# ESP32-H4 register map
Vendor: ESPRESSIF SYSTEMS (SHANGHAI) CO., LTD.; Series: ESP32 H-Series; File version: 1
CPU: RV32IMAC r0p0, little endian, no MPU, no FPU, 0 interrupt priority bits
Address unit: 32 bits
Registers are 32-bit, read-write, reset 0x0 unless marked. A register's access mark holds for its fields unless they carry their own. Offsets are from the block's base; [hi:lo] are bit positions.

## TEE (part 2 of 2) — TEE Peripheral
Base 0x6009F000
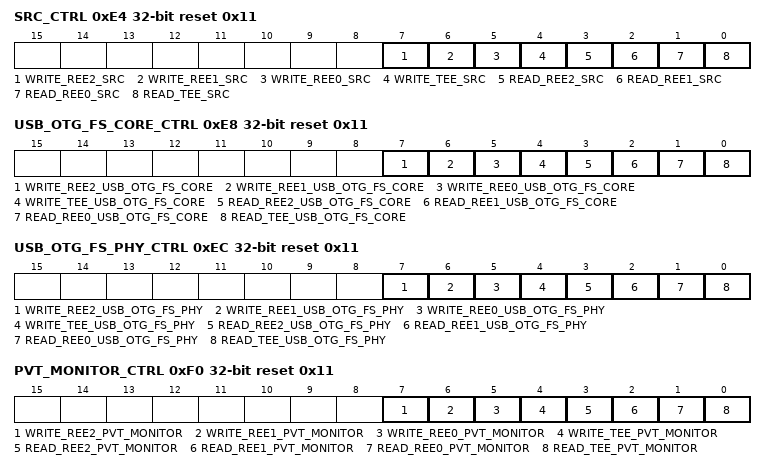
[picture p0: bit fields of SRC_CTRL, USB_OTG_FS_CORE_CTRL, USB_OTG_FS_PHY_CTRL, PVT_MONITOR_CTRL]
0xE4 SRC_CTRL reset 0x11 — src read/write control register
  [7] WRITE_REE2_SRC — Configures src registers write permission in ree2 mode.\\ 0: can not be write \\ 1: can be write \\
  [6] WRITE_REE1_SRC — Configures src registers write permission in ree1 mode.\\ 0: can not be write \\ 1: can be write \\
  [5] WRITE_REE0_SRC — Configures src registers write permission in ree0 mode.\\ 0: can not be write \\ 1: can be write \\
  [4] WRITE_TEE_SRC — Configures src registers write permission in tee mode.\\ 0: can not be write \\ 1: can be write \\
  [3] READ_REE2_SRC — Configures src registers read permission in ree2 mode.\\ 0: can not be read \\ 1: can be read \\
  [2] READ_REE1_SRC — Configures src registers read permission in ree1 mode.\\ 0: can not be read \\ 1: can be read \\
  [1] READ_REE0_SRC — Configures src registers read permission in ree0 mode.\\ 0: can not be read \\ 1: can be read \\
  [0] READ_TEE_SRC — Configures src registers read permission in tee mode.\\ 0: can not be read \\ 1: can be read \\
0xE8 USB_OTG_FS_CORE_CTRL reset 0x11 — usb_otg_fs_core read/write control register
  [7] WRITE_REE2_USB_OTG_FS_CORE — Configures usb_otg_fs_core registers write permission in ree2 mode.\\ 0: can not be write \\ 1: can be write \\
  [6] WRITE_REE1_USB_OTG_FS_CORE — Configures usb_otg_fs_core registers write permission in ree1 mode.\\ 0: can not be write \\ 1: can be write \\
  [5] WRITE_REE0_USB_OTG_FS_CORE — Configures usb_otg_fs_core registers write permission in ree0 mode.\\ 0: can not be write \\ 1: can be write \\
  [4] WRITE_TEE_USB_OTG_FS_CORE — Configures usb_otg_fs_core registers write permission in tee mode.\\ 0: can not be write \\ 1: can be write \\
  [3] READ_REE2_USB_OTG_FS_CORE — Configures usb_otg_fs_core registers read permission in ree2 mode.\\ 0: can not be read \\ 1: can be read \\
  [2] READ_REE1_USB_OTG_FS_CORE — Configures usb_otg_fs_core registers read permission in ree1 mode.\\ 0: can not be read \\ 1: can be read \\
  [1] READ_REE0_USB_OTG_FS_CORE — Configures usb_otg_fs_core registers read permission in ree0 mode.\\ 0: can not be read \\ 1: can be read \\
  [0] READ_TEE_USB_OTG_FS_CORE — Configures usb_otg_fs_core registers read permission in tee mode.\\ 0: can not be read \\ 1: can be read \\
0xEC USB_OTG_FS_PHY_CTRL reset 0x11 — usb_otg_fs_phy read/write control register
  [7] WRITE_REE2_USB_OTG_FS_PHY — Configures usb_otg_fs_phy registers write permission in ree2 mode.\\ 0: can not be write \\ 1: can be write \\
  [6] WRITE_REE1_USB_OTG_FS_PHY — Configures usb_otg_fs_phy registers write permission in ree1 mode.\\ 0: can not be write \\ 1: can be write \\
  [5] WRITE_REE0_USB_OTG_FS_PHY — Configures usb_otg_fs_phy registers write permission in ree0 mode.\\ 0: can not be write \\ 1: can be write \\
  [4] WRITE_TEE_USB_OTG_FS_PHY — Configures usb_otg_fs_phy registers write permission in tee mode.\\ 0: can not be write \\ 1: can be write \\
  [3] READ_REE2_USB_OTG_FS_PHY — Configures usb_otg_fs_phy registers read permission in ree2 mode.\\ 0: can not be read \\ 1: can be read \\
  [2] READ_REE1_USB_OTG_FS_PHY — Configures usb_otg_fs_phy registers read permission in ree1 mode.\\ 0: can not be read \\ 1: can be read \\
  [1] READ_REE0_USB_OTG_FS_PHY — Configures usb_otg_fs_phy registers read permission in ree0 mode.\\ 0: can not be read \\ 1: can be read \\
  [0] READ_TEE_USB_OTG_FS_PHY — Configures usb_otg_fs_phy registers read permission in tee mode.\\ 0: can not be read \\ 1: can be read \\
0xF0 PVT_MONITOR_CTRL reset 0x11 — pvt_monitor read/write control register
  [7] WRITE_REE2_PVT_MONITOR — Configures pvt_monitor registers write permission in ree2 mode.\\ 0: can not be write \\ 1: can be write \\
  [6] WRITE_REE1_PVT_MONITOR — Configures pvt_monitor registers write permission in ree1 mode.\\ 0: can not be write \\ 1: can be write \\
  [5] WRITE_REE0_PVT_MONITOR — Configures pvt_monitor registers write permission in ree0 mode.\\ 0: can not be write \\ 1: can be write \\
  [4] WRITE_TEE_PVT_MONITOR — Configures pvt_monitor registers write permission in tee mode.\\ 0: can not be write \\ 1: can be write \\
  [3] READ_REE2_PVT_MONITOR — Configures pvt_monitor registers read permission in ree2 mode.\\ 0: can not be read \\ 1: can be read \\
  [2] READ_REE1_PVT_MONITOR — Configures pvt_monitor registers read permission in ree1 mode.\\ 0: can not be read \\ 1: can be read \\
  [1] READ_REE0_PVT_MONITOR — Configures pvt_monitor registers read permission in ree0 mode.\\ 0: can not be read \\ 1: can be read \\
  [0] READ_TEE_PVT_MONITOR — Configures pvt_monitor registers read permission in tee mode.\\ 0: can not be read \\ 1: can be read \\
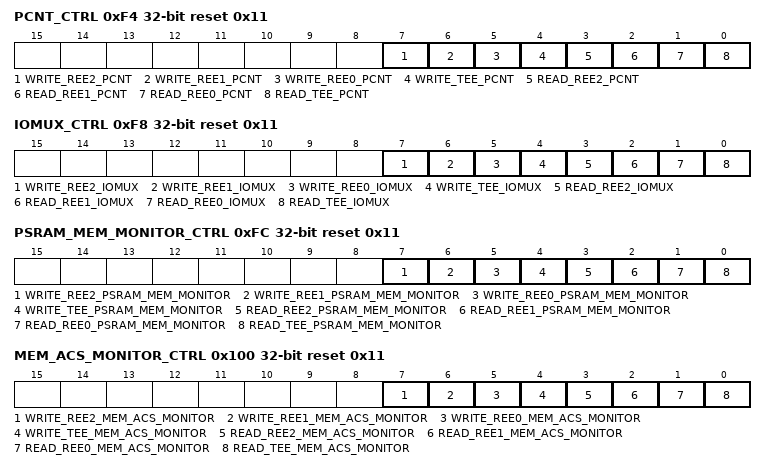
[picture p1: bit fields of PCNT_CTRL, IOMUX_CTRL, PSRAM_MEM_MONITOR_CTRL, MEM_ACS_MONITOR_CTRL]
0xF4 PCNT_CTRL reset 0x11 — pcnt read/write control register
  [7] WRITE_REE2_PCNT — Configures pcnt registers write permission in ree2 mode.\\ 0: can not be write \\ 1: can be write \\
  [6] WRITE_REE1_PCNT — Configures pcnt registers write permission in ree1 mode.\\ 0: can not be write \\ 1: can be write \\
  [5] WRITE_REE0_PCNT — Configures pcnt registers write permission in ree0 mode.\\ 0: can not be write \\ 1: can be write \\
  [4] WRITE_TEE_PCNT — Configures pcnt registers write permission in tee mode.\\ 0: can not be write \\ 1: can be write \\
  [3] READ_REE2_PCNT — Configures pcnt registers read permission in ree2 mode.\\ 0: can not be read \\ 1: can be read \\
  [2] READ_REE1_PCNT — Configures pcnt registers read permission in ree1 mode.\\ 0: can not be read \\ 1: can be read \\
  [1] READ_REE0_PCNT — Configures pcnt registers read permission in ree0 mode.\\ 0: can not be read \\ 1: can be read \\
  [0] READ_TEE_PCNT — Configures pcnt registers read permission in tee mode.\\ 0: can not be read \\ 1: can be read \\
0xF8 IOMUX_CTRL reset 0x11 — iomux read/write control register
  [7] WRITE_REE2_IOMUX — Configures iomux registers write permission in ree2 mode.\\ 0: can not be write \\ 1: can be write \\
  [6] WRITE_REE1_IOMUX — Configures iomux registers write permission in ree1 mode.\\ 0: can not be write \\ 1: can be write \\
  [5] WRITE_REE0_IOMUX — Configures iomux registers write permission in ree0 mode.\\ 0: can not be write \\ 1: can be write \\
  [4] WRITE_TEE_IOMUX — Configures iomux registers write permission in tee mode.\\ 0: can not be write \\ 1: can be write \\
  [3] READ_REE2_IOMUX — Configures iomux registers read permission in ree2 mode.\\ 0: can not be read \\ 1: can be read \\
  [2] READ_REE1_IOMUX — Configures iomux registers read permission in ree1 mode.\\ 0: can not be read \\ 1: can be read \\
  [1] READ_REE0_IOMUX — Configures iomux registers read permission in ree0 mode.\\ 0: can not be read \\ 1: can be read \\
  [0] READ_TEE_IOMUX — Configures iomux registers read permission in tee mode.\\ 0: can not be read \\ 1: can be read \\
0xFC PSRAM_MEM_MONITOR_CTRL reset 0x11 — psram_mem_monitor read/write control register
  [7] WRITE_REE2_PSRAM_MEM_MONITOR — Configures psram_mem_monitor registers write permission in ree2 mode.\\ 0: can not be write \\ 1: can be write \\
  [6] WRITE_REE1_PSRAM_MEM_MONITOR — Configures psram_mem_monitor registers write permission in ree1 mode.\\ 0: can not be write \\ 1: can be write \\
  [5] WRITE_REE0_PSRAM_MEM_MONITOR — Configures psram_mem_monitor registers write permission in ree0 mode.\\ 0: can not be write \\ 1: can be write \\
  [4] WRITE_TEE_PSRAM_MEM_MONITOR — Configures psram_mem_monitor registers write permission in tee mode.\\ 0: can not be write \\ 1: can be write \\
  [3] READ_REE2_PSRAM_MEM_MONITOR — Configures psram_mem_monitor registers read permission in ree2 mode.\\ 0: can not be read \\ 1: can be read \\
  [2] READ_REE1_PSRAM_MEM_MONITOR — Configures psram_mem_monitor registers read permission in ree1 mode.\\ 0: can not be read \\ 1: can be read \\
  [1] READ_REE0_PSRAM_MEM_MONITOR — Configures psram_mem_monitor registers read permission in ree0 mode.\\ 0: can not be read \\ 1: can be read \\
  [0] READ_TEE_PSRAM_MEM_MONITOR — Configures psram_mem_monitor registers read permission in tee mode.\\ 0: can not be read \\ 1: can be read \\
0x100 MEM_ACS_MONITOR_CTRL reset 0x11 — mem_acs_monitor read/write control register
  [7] WRITE_REE2_MEM_ACS_MONITOR — Configures mem_acs_monitor registers write permission in ree2 mode.\\ 0: can not be write \\ 1: can be write \\
  [6] WRITE_REE1_MEM_ACS_MONITOR — Configures mem_acs_monitor registers write permission in ree1 mode.\\ 0: can not be write \\ 1: can be write \\
  [5] WRITE_REE0_MEM_ACS_MONITOR — Configures mem_acs_monitor registers write permission in ree0 mode.\\ 0: can not be write \\ 1: can be write \\
  [4] WRITE_TEE_MEM_ACS_MONITOR — Configures mem_acs_monitor registers write permission in tee mode.\\ 0: can not be write \\ 1: can be write \\
  [3] READ_REE2_MEM_ACS_MONITOR — Configures mem_acs_monitor registers read permission in ree2 mode.\\ 0: can not be read \\ 1: can be read \\
  [2] READ_REE1_MEM_ACS_MONITOR — Configures mem_acs_monitor registers read permission in ree1 mode.\\ 0: can not be read \\ 1: can be read \\
  [1] READ_REE0_MEM_ACS_MONITOR — Configures mem_acs_monitor registers read permission in ree0 mode.\\ 0: can not be read \\ 1: can be read \\
  [0] READ_TEE_MEM_ACS_MONITOR — Configures mem_acs_monitor registers read permission in tee mode.\\ 0: can not be read \\ 1: can be read \\
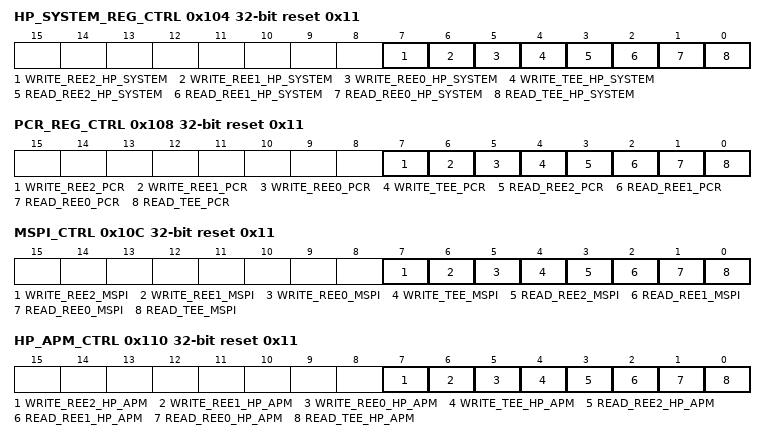
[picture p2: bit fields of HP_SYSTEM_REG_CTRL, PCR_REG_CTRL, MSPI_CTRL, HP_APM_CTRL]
0x104 HP_SYSTEM_REG_CTRL reset 0x11 — hp_system_reg read/write control register
  [7] WRITE_REE2_HP_SYSTEM — Configures hp_system_reg registers write permission in ree2 mode.\\ 0: can not be write \\ 1: can be write \\
  [6] WRITE_REE1_HP_SYSTEM — Configures hp_system_reg registers write permission in ree1 mode.\\ 0: can not be write \\ 1: can be write \\
  [5] WRITE_REE0_HP_SYSTEM — Configures hp_system_reg registers write permission in ree0 mode.\\ 0: can not be write \\ 1: can be write \\
  [4] WRITE_TEE_HP_SYSTEM — Configures hp_system_reg registers write permission in tee mode.\\ 0: can not be write \\ 1: can be write \\
  [3] READ_REE2_HP_SYSTEM — Configures hp_system_reg registers read permission in ree2 mode.\\ 0: can not be read \\ 1: can be read \\
  [2] READ_REE1_HP_SYSTEM — Configures hp_system_reg registers read permission in ree1 mode.\\ 0: can not be read \\ 1: can be read \\
  [1] READ_REE0_HP_SYSTEM — Configures hp_system_reg registers read permission in ree0 mode.\\ 0: can not be read \\ 1: can be read \\
  [0] READ_TEE_HP_SYSTEM — Configures hp_system_reg registers read permission in tee mode.\\ 0: can not be read \\ 1: can be read \\
0x108 PCR_REG_CTRL reset 0x11 — pcr_reg read/write control register
  [7] WRITE_REE2_PCR — Configures pcr_reg registers write permission in ree2 mode.\\ 0: can not be write \\ 1: can be write \\
  [6] WRITE_REE1_PCR — Configures pcr_reg registers write permission in ree1 mode.\\ 0: can not be write \\ 1: can be write \\
  [5] WRITE_REE0_PCR — Configures pcr_reg registers write permission in ree0 mode.\\ 0: can not be write \\ 1: can be write \\
  [4] WRITE_TEE_PCR — Configures pcr_reg registers write permission in tee mode.\\ 0: can not be write \\ 1: can be write \\
  [3] READ_REE2_PCR — Configures pcr_reg registers read permission in ree2 mode.\\ 0: can not be read \\ 1: can be read \\
  [2] READ_REE1_PCR — Configures pcr_reg registers read permission in ree1 mode.\\ 0: can not be read \\ 1: can be read \\
  [1] READ_REE0_PCR — Configures pcr_reg registers read permission in ree0 mode.\\ 0: can not be read \\ 1: can be read \\
  [0] READ_TEE_PCR — Configures pcr_reg registers read permission in tee mode.\\ 0: can not be read \\ 1: can be read \\
0x10C MSPI_CTRL reset 0x11 — mspi read/write control register
  [7] WRITE_REE2_MSPI — Configures mspi registers write permission in ree2 mode.\\ 0: can not be write \\ 1: can be write \\
  [6] WRITE_REE1_MSPI — Configures mspi registers write permission in ree1 mode.\\ 0: can not be write \\ 1: can be write \\
  [5] WRITE_REE0_MSPI — Configures mspi registers write permission in ree0 mode.\\ 0: can not be write \\ 1: can be write \\
  [4] WRITE_TEE_MSPI — Configures mspi registers write permission in tee mode.\\ 0: can not be write \\ 1: can be write \\
  [3] READ_REE2_MSPI — Configures mspi registers read permission in ree2 mode.\\ 0: can not be read \\ 1: can be read \\
  [2] READ_REE1_MSPI — Configures mspi registers read permission in ree1 mode.\\ 0: can not be read \\ 1: can be read \\
  [1] READ_REE0_MSPI — Configures mspi registers read permission in ree0 mode.\\ 0: can not be read \\ 1: can be read \\
  [0] READ_TEE_MSPI — Configures mspi registers read permission in tee mode.\\ 0: can not be read \\ 1: can be read \\
0x110 HP_APM_CTRL access per field reset 0x11 — hp_apm read/write control register
  [7] WRITE_REE2_HP_APM ro — Configures hp_apm registers write permission in ree2 mode.\\ 0: can not be write \\ 1: can be write \\
  [6] WRITE_REE1_HP_APM ro — Configures hp_apm registers write permission in ree1 mode.\\ 0: can not be write \\ 1: can be write \\
  [5] WRITE_REE0_HP_APM ro — Configures hp_apm registers write permission in ree0 mode.\\ 0: can not be write \\ 1: can be write \\
  [4] WRITE_TEE_HP_APM rw — Configures hp_apm registers write permission in tee mode.\\ 0: can not be write \\ 1: can be write \\
  [3] READ_REE2_HP_APM ro — Configures hp_apm registers read permission in ree2 mode.\\ 0: can not be read \\ 1: can be read \\
  [2] READ_REE1_HP_APM ro — Configures hp_apm registers read permission in ree1 mode.\\ 0: can not be read \\ 1: can be read \\
  [1] READ_REE0_HP_APM ro — Configures hp_apm registers read permission in ree0 mode.\\ 0: can not be read \\ 1: can be read \\
  [0] READ_TEE_HP_APM rw — Configures hp_apm registers read permission in tee mode.\\ 0: can not be read \\ 1: can be read \\
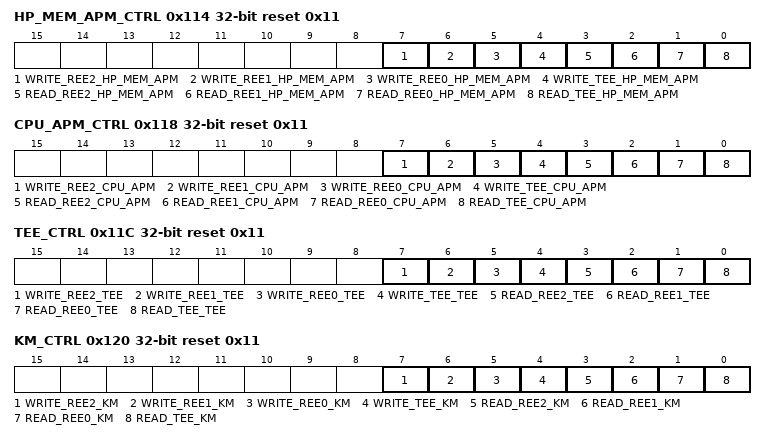
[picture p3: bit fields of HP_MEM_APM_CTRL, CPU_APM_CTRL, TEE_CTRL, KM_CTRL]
0x114 HP_MEM_APM_CTRL access per field reset 0x11 — hp_mem_apm read/write control register
  [7] WRITE_REE2_HP_MEM_APM ro — Configures hp_mem_apm registers write permission in ree2 mode.\\ 0: can not be write \\ 1: can be write \\
  [6] WRITE_REE1_HP_MEM_APM ro — Configures hp_mem_apm registers write permission in ree1 mode.\\ 0: can not be write \\ 1: can be write \\
  [5] WRITE_REE0_HP_MEM_APM ro — Configures hp_mem_apm registers write permission in ree0 mode.\\ 0: can not be write \\ 1: can be write \\
  [4] WRITE_TEE_HP_MEM_APM rw — Configures hp_mem_apm registers write permission in tee mode.\\ 0: can not be write \\ 1: can be write \\
  [3] READ_REE2_HP_MEM_APM ro — Configures hp_mem_apm registers read permission in ree2 mode.\\ 0: can not be read \\ 1: can be read \\
  [2] READ_REE1_HP_MEM_APM ro — Configures hp_mem_apm registers read permission in ree1 mode.\\ 0: can not be read \\ 1: can be read \\
  [1] READ_REE0_HP_MEM_APM ro — Configures hp_mem_apm registers read permission in ree0 mode.\\ 0: can not be read \\ 1: can be read \\
  [0] READ_TEE_HP_MEM_APM rw — Configures hp_mem_apm registers read permission in tee mode.\\ 0: can not be read \\ 1: can be read \\
0x118 CPU_APM_CTRL access per field reset 0x11 — cpu_apm read/write control register
  [7] WRITE_REE2_CPU_APM ro — Configures cpu_apm registers write permission in ree2 mode.\\ 0: can not be write \\ 1: can be write \\
  [6] WRITE_REE1_CPU_APM ro — Configures cpu_apm registers write permission in ree1 mode.\\ 0: can not be write \\ 1: can be write \\
  [5] WRITE_REE0_CPU_APM ro — Configures cpu_apm registers write permission in ree0 mode.\\ 0: can not be write \\ 1: can be write \\
  [4] WRITE_TEE_CPU_APM rw — Configures cpu_apm registers write permission in tee mode.\\ 0: can not be write \\ 1: can be write \\
  [3] READ_REE2_CPU_APM ro — Configures cpu_apm registers read permission in ree2 mode.\\ 0: can not be read \\ 1: can be read \\
  [2] READ_REE1_CPU_APM ro — Configures cpu_apm registers read permission in ree1 mode.\\ 0: can not be read \\ 1: can be read \\
  [1] READ_REE0_CPU_APM ro — Configures cpu_apm registers read permission in ree0 mode.\\ 0: can not be read \\ 1: can be read \\
  [0] READ_TEE_CPU_APM rw — Configures cpu_apm registers read permission in tee mode.\\ 0: can not be read \\ 1: can be read \\
0x11C TEE_CTRL access per field reset 0x11 — tee read/write control register
  [7] WRITE_REE2_TEE ro — Configures tee registers write permission in ree2 mode.\\ 0: can not be write \\ 1: can be write \\
  [6] WRITE_REE1_TEE ro — Configures tee registers write permission in ree1 mode.\\ 0: can not be write \\ 1: can be write \\
  [5] WRITE_REE0_TEE ro — Configures tee registers write permission in ree0 mode.\\ 0: can not be write \\ 1: can be write \\
  [4] WRITE_TEE_TEE rw — Configures tee registers write permission in tee mode.\\ 0: can not be write \\ 1: can be write \\
  [3] READ_REE2_TEE ro — Configures tee registers read permission in ree2 mode.\\ 0: can not be read \\ 1: can be read \\
  [2] READ_REE1_TEE ro — Configures tee registers read permission in ree1 mode.\\ 0: can not be read \\ 1: can be read \\
  [1] READ_REE0_TEE ro — Configures tee registers read permission in ree0 mode.\\ 0: can not be read \\ 1: can be read \\
  [0] READ_TEE_TEE rw — Configures tee registers read permission in tee mode.\\ 0: can not be read \\ 1: can be read \\
0x120 KM_CTRL reset 0x11 — crypt read/write control register
  [7] WRITE_REE2_KM — Configures km registers write permission in ree2 mode.\\ 0: can not be write \\ 1: can be write \\
  [6] WRITE_REE1_KM — Configures km registers write permission in ree1 mode.\\ 0: can not be write \\ 1: can be write \\
  [5] WRITE_REE0_KM — Configures km registers write permission in ree0 mode.\\ 0: can not be write \\ 1: can be write \\
  [4] WRITE_TEE_KM — Configures km registers write permission in tee mode.\\ 0: can not be write \\ 1: can be write \\
  [3] READ_REE2_KM — Configures km registers read permission in ree2 mode.\\ 0: can not be read \\ 1: can be read \\
  [2] READ_REE1_KM — Configures km registers read permission in ree1 mode.\\ 0: can not be read \\ 1: can be read \\
  [1] READ_REE0_KM — Configures km registers read permission in ree0 mode.\\ 0: can not be read \\ 1: can be read \\
  [0] READ_TEE_KM — Configures km registers read permission in tee mode.\\ 0: can not be read \\ 1: can be read \\
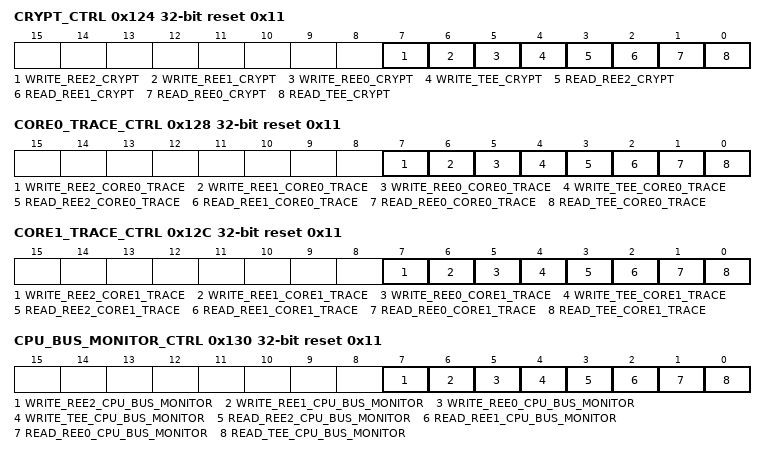
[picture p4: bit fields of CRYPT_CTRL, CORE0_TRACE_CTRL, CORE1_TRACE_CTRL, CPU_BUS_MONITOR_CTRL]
0x124 CRYPT_CTRL reset 0x11 — crypt read/write control register
  [7] WRITE_REE2_CRYPT — Configures crypt registers write permission in ree2 mode.\\ 0: can not be write \\ 1: can be write \\
  [6] WRITE_REE1_CRYPT — Configures crypt registers write permission in ree1 mode.\\ 0: can not be write \\ 1: can be write \\
  [5] WRITE_REE0_CRYPT — Configures crypt registers write permission in ree0 mode.\\ 0: can not be write \\ 1: can be write \\
  [4] WRITE_TEE_CRYPT — Configures crypt registers write permission in tee mode.\\ 0: can not be write \\ 1: can be write \\
  [3] READ_REE2_CRYPT — Configures crypt registers read permission in ree2 mode.\\ 0: can not be read \\ 1: can be read \\
  [2] READ_REE1_CRYPT — Configures crypt registers read permission in ree1 mode.\\ 0: can not be read \\ 1: can be read \\
  [1] READ_REE0_CRYPT — Configures crypt registers read permission in ree0 mode.\\ 0: can not be read \\ 1: can be read \\
  [0] READ_TEE_CRYPT — Configures crypt registers read permission in tee mode.\\ 0: can not be read \\ 1: can be read \\
0x128 CORE0_TRACE_CTRL reset 0x11 — core0_trace read/write control register
  [7] WRITE_REE2_CORE0_TRACE — Configures core0_trace registers write permission in ree2 mode.\\ 0: can not be write \\ 1: can be write \\
  [6] WRITE_REE1_CORE0_TRACE — Configures core0_trace registers write permission in ree1 mode.\\ 0: can not be write \\ 1: can be write \\
  [5] WRITE_REE0_CORE0_TRACE — Configures core0_trace registers write permission in ree0 mode.\\ 0: can not be write \\ 1: can be write \\
  [4] WRITE_TEE_CORE0_TRACE — Configures core0_trace registers write permission in tee mode.\\ 0: can not be write \\ 1: can be write \\
  [3] READ_REE2_CORE0_TRACE — Configures core0_trace registers read permission in ree2 mode.\\ 0: can not be read \\ 1: can be read \\
  [2] READ_REE1_CORE0_TRACE — Configures core0_trace registers read permission in ree1 mode.\\ 0: can not be read \\ 1: can be read \\
  [1] READ_REE0_CORE0_TRACE — Configures core0_trace registers read permission in ree0 mode.\\ 0: can not be read \\ 1: can be read \\
  [0] READ_TEE_CORE0_TRACE — Configures core0_trace registers read permission in tee mode.\\ 0: can not be read \\ 1: can be read \\
0x12C CORE1_TRACE_CTRL reset 0x11 — core1_trace read/write control register
  [7] WRITE_REE2_CORE1_TRACE — Configures core1_trace registers write permission in ree2 mode.\\ 0: can not be write \\ 1: can be write \\
  [6] WRITE_REE1_CORE1_TRACE — Configures core1_trace registers write permission in ree1 mode.\\ 0: can not be write \\ 1: can be write \\
  [5] WRITE_REE0_CORE1_TRACE — Configures core1_trace registers write permission in ree0 mode.\\ 0: can not be write \\ 1: can be write \\
  [4] WRITE_TEE_CORE1_TRACE — Configures core1_trace registers write permission in tee mode.\\ 0: can not be write \\ 1: can be write \\
  [3] READ_REE2_CORE1_TRACE — Configures core1_trace registers read permission in ree2 mode.\\ 0: can not be read \\ 1: can be read \\
  [2] READ_REE1_CORE1_TRACE — Configures core1_trace registers read permission in ree1 mode.\\ 0: can not be read \\ 1: can be read \\
  [1] READ_REE0_CORE1_TRACE — Configures core1_trace registers read permission in ree0 mode.\\ 0: can not be read \\ 1: can be read \\
  [0] READ_TEE_CORE1_TRACE — Configures core1_trace registers read permission in tee mode.\\ 0: can not be read \\ 1: can be read \\
0x130 CPU_BUS_MONITOR_CTRL reset 0x11 — cpu_bus_monitor read/write control register
  [7] WRITE_REE2_CPU_BUS_MONITOR — Configures cpu_bus_monitor registers write permission in ree2 mode.\\ 0: can not be write \\ 1: can be write \\
  [6] WRITE_REE1_CPU_BUS_MONITOR — Configures cpu_bus_monitor registers write permission in ree1 mode.\\ 0: can not be write \\ 1: can be write \\
  [5] WRITE_REE0_CPU_BUS_MONITOR — Configures cpu_bus_monitor registers write permission in ree0 mode.\\ 0: can not be write \\ 1: can be write \\
  [4] WRITE_TEE_CPU_BUS_MONITOR — Configures cpu_bus_monitor registers write permission in tee mode.\\ 0: can not be write \\ 1: can be write \\
  [3] READ_REE2_CPU_BUS_MONITOR — Configures cpu_bus_monitor registers read permission in ree2 mode.\\ 0: can not be read \\ 1: can be read \\
  [2] READ_REE1_CPU_BUS_MONITOR — Configures cpu_bus_monitor registers read permission in ree1 mode.\\ 0: can not be read \\ 1: can be read \\
  [1] READ_REE0_CPU_BUS_MONITOR — Configures cpu_bus_monitor registers read permission in ree0 mode.\\ 0: can not be read \\ 1: can be read \\
  [0] READ_TEE_CPU_BUS_MONITOR — Configures cpu_bus_monitor registers read permission in tee mode.\\ 0: can not be read \\ 1: can be read \\
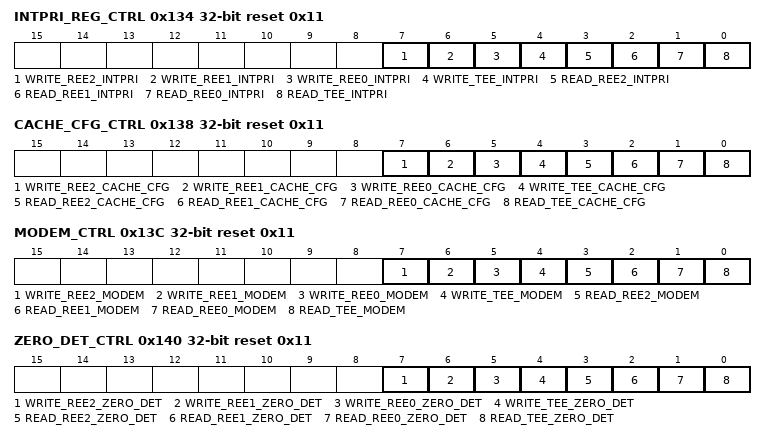
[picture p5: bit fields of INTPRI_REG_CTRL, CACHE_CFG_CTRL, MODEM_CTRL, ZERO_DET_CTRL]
0x134 INTPRI_REG_CTRL reset 0x11 — intpri_reg read/write control register
  [7] WRITE_REE2_INTPRI — Configures intpri_reg registers write permission in ree2 mode.\\ 0: can not be write \\ 1: can be write \\
  [6] WRITE_REE1_INTPRI — Configures intpri_reg registers write permission in ree1 mode.\\ 0: can not be write \\ 1: can be write \\
  [5] WRITE_REE0_INTPRI — Configures intpri_reg registers write permission in ree0 mode.\\ 0: can not be write \\ 1: can be write \\
  [4] WRITE_TEE_INTPRI — Configures intpri_reg registers write permission in tee mode.\\ 0: can not be write \\ 1: can be write \\
  [3] READ_REE2_INTPRI — Configures intpri_reg registers read permission in ree2 mode.\\ 0: can not be read \\ 1: can be read \\
  [2] READ_REE1_INTPRI — Configures intpri_reg registers read permission in ree1 mode.\\ 0: can not be read \\ 1: can be read \\
  [1] READ_REE0_INTPRI — Configures intpri_reg registers read permission in ree0 mode.\\ 0: can not be read \\ 1: can be read \\
  [0] READ_TEE_INTPRI — Configures intpri_reg registers read permission in tee mode.\\ 0: can not be read \\ 1: can be read \\
0x138 CACHE_CFG_CTRL reset 0x11 — cache_cfg read/write control register
  [7] WRITE_REE2_CACHE_CFG — Configures cache_cfg registers write permission in ree2 mode.\\ 0: can not be write \\ 1: can be write \\
  [6] WRITE_REE1_CACHE_CFG — Configures cache_cfg registers write permission in ree1 mode.\\ 0: can not be write \\ 1: can be write \\
  [5] WRITE_REE0_CACHE_CFG — Configures cache_cfg registers write permission in ree0 mode.\\ 0: can not be write \\ 1: can be write \\
  [4] WRITE_TEE_CACHE_CFG — Configures cache_cfg registers write permission in tee mode.\\ 0: can not be write \\ 1: can be write \\
  [3] READ_REE2_CACHE_CFG — Configures cache_cfg registers read permission in ree2 mode.\\ 0: can not be read \\ 1: can be read \\
  [2] READ_REE1_CACHE_CFG — Configures cache_cfg registers read permission in ree1 mode.\\ 0: can not be read \\ 1: can be read \\
  [1] READ_REE0_CACHE_CFG — Configures cache_cfg registers read permission in ree0 mode.\\ 0: can not be read \\ 1: can be read \\
  [0] READ_TEE_CACHE_CFG — Configures cache_cfg registers read permission in tee mode.\\ 0: can not be read \\ 1: can be read \\
0x13C MODEM_CTRL reset 0x11 — modem read/write control register
  [7] WRITE_REE2_MODEM — Configures modem registers write permission in ree2 mode.\\ 0: can not be write \\ 1: can be write \\
  [6] WRITE_REE1_MODEM — Configures modem registers write permission in ree1 mode.\\ 0: can not be write \\ 1: can be write \\
  [5] WRITE_REE0_MODEM — Configures modem registers write permission in ree0 mode.\\ 0: can not be write \\ 1: can be write \\
  [4] WRITE_TEE_MODEM — Configures modem registers write permission in tee mode.\\ 0: can not be write \\ 1: can be write \\
  [3] READ_REE2_MODEM — Configures modem registers read permission in ree2 mode.\\ 0: can not be read \\ 1: can be read \\
  [2] READ_REE1_MODEM — Configures modem registers read permission in ree1 mode.\\ 0: can not be read \\ 1: can be read \\
  [1] READ_REE0_MODEM — Configures modem registers read permission in ree0 mode.\\ 0: can not be read \\ 1: can be read \\
  [0] READ_TEE_MODEM — Configures modem registers read permission in tee mode.\\ 0: can not be read \\ 1: can be read \\
0x140 ZERO_DET_CTRL reset 0x11 — zero_det read/write control register
  [7] WRITE_REE2_ZERO_DET — Configures zero_det registers write permission in ree2 mode.\\ 0: can not be write \\ 1: can be write \\
  [6] WRITE_REE1_ZERO_DET — Configures zero_det registers write permission in ree1 mode.\\ 0: can not be write \\ 1: can be write \\
  [5] WRITE_REE0_ZERO_DET — Configures zero_det registers write permission in ree0 mode.\\ 0: can not be write \\ 1: can be write \\
  [4] WRITE_TEE_ZERO_DET — Configures zero_det registers write permission in tee mode.\\ 0: can not be write \\ 1: can be write \\
  [3] READ_REE2_ZERO_DET — Configures zero_det registers read permission in ree2 mode.\\ 0: can not be read \\ 1: can be read \\
  [2] READ_REE1_ZERO_DET — Configures zero_det registers read permission in ree1 mode.\\ 0: can not be read \\ 1: can be read \\
  [1] READ_REE0_ZERO_DET — Configures zero_det registers read permission in ree0 mode.\\ 0: can not be read \\ 1: can be read \\
  [0] READ_TEE_ZERO_DET — Configures zero_det registers read permission in tee mode.\\ 0: can not be read \\ 1: can be read \\
0xFF0 BUS_ERR_CONF — Clock gating register
  [0] BUS_ERR_RESP_EN — Configures whether return error response to cpu when access blocked 0: disable error response \\ 1: enable error response \\
0xFF8 CLOCK_GATE reset 0x1 — Clock gating register
  [0] CLK_EN — Configures whether to keep the clock always on.\\ 0: enable automatic clock gating \\ 1: keep the clock always on \\
0xFFC DATE reset 0x2503280 — Version control register
  [27:0] DATE
